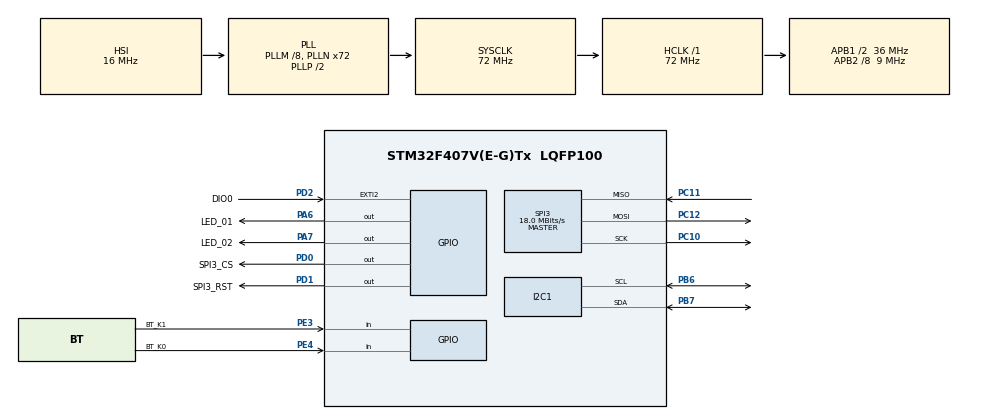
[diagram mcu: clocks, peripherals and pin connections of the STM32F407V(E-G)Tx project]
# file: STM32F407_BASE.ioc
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Mcu.Family=STM32F4
Mcu.Name=STM32F407V(E-G)Tx
Mcu.Package=LQFP100
NVIC.PriorityGroup=NVIC_PRIORITYGROUP_4
NVIC.RCC_IRQn=true\:0\:0\:false\:false\:true\:true\:false\:true
NVIC.TIM1_UP_TIM10_IRQn=true\:0\:0\:false\:false\:true\:true\:true\:true
PA13.Mode=Serial_Wire
PA13.Signal=SYS_JTMS-SWDIO
PA14.Mode=Serial_Wire
PA14.Signal=SYS_JTCK-SWCLK
PA6.GPIO_Label=LED_01
PA6.GPIO_PuPd=GPIO_PULLUP
PA6.Signal=GPIO_Output
PA7.GPIO_Label=LED_02
PA7.GPIO_PuPd=GPIO_PULLUP
PA7.Signal=GPIO_Output
PB6.Mode=I2C
PB6.Signal=I2C1_SCL
PB7.Mode=I2C
PB7.Signal=I2C1_SDA
PC10.Mode=Full_Duplex_Master
PC10.Signal=SPI3_SCK
PC11.Mode=Full_Duplex_Master
PC11.Signal=SPI3_MISO
PC12.Mode=Full_Duplex_Master
PC12.Signal=SPI3_MOSI
PD0.GPIO_Label=SPI3_CS
PD0.PinState=GPIO_PIN_SET
PD0.Signal=GPIO_Output
PD1.GPIO_Label=SPI3_RST
PD1.PinState=GPIO_PIN_SET
PD1.Signal=GPIO_Output
PD2.GPIO_Label=DIO0
PD2.Signal=GPXTI2
PE3.GPIO_Label=BT_K1
PE3.GPIO_PuPd=GPIO_PULLUP
PE3.Signal=GPIO_Input
PE4.GPIO_Label=BT_K0
PE4.GPIO_PuPd=GPIO_PULLUP
PE4.Signal=GPIO_Input
PH0-OSC_IN.Mode=HSE-External-Oscillator
PH0-OSC_IN.Signal=RCC_OSC_IN
PH1-OSC_OUT.Mode=HSE-External-Oscillator
PH1-OSC_OUT.Signal=RCC_OSC_OUT
ProjectManager.HeapSize=0x200
ProjectManager.StackSize=0x400
ProjectManager.TargetToolchain=STM32CubeIDE
RCC.48MHZClocksFreq_Value=36000000
RCC.AHBFreq_Value=72000000
RCC.APB1CLKDivider=RCC_HCLK_DIV2
RCC.APB1Freq_Value=36000000
RCC.APB1TimFreq_Value=72000000
RCC.APB2CLKDivider=RCC_HCLK_DIV8
RCC.APB2Freq_Value=9000000
RCC.APB2TimFreq_Value=18000000
RCC.CortexFreq_Value=72000000
RCC.HCLKFreq_Value=72000000
RCC.HSE_VALUE=25000000
RCC.HSI_VALUE=16000000
RCC.LSE_VALUE=32768
RCC.PLLM=8
RCC.PLLN=72
RCC.SYSCLKFreq_VALUE=72000000
RCC.SYSCLKSource=RCC_SYSCLKSOURCE_PLLCLK
RCC.VCOOutputFreq_Value=144000000
SPI3.BaudRatePrescaler=SPI_BAUDRATEPRESCALER_2
SPI3.CalculateBaudRate=18.0 MBits/s
SPI3.Direction=SPI_DIRECTION_2LINES
SPI3.Mode=SPI_MODE_MASTER
SPI3.VirtualType=VM_MASTER
TIM1.Period=99
TIM1.Prescaler=9000
VP_TIM1_VS_ClockSourceINT.Mode=Internal
board=custom

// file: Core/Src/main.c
/* USER CODE BEGIN Header */
/**
  ******************************************************************************
  * @file           : main.c
  * @brief          : Main program body
  ******************************************************************************
  */
/* USER CODE END Header */
#include "main.h"
#include "i2c-lcd.h"
#include "LoRa_Frame.h"

I2C_HandleTypeDef hi2c1;

SPI_HandleTypeDef hspi3;

TIM_HandleTypeDef htim1;

/* USER CODE BEGIN PV */

uint32_t last_send_tick = 0;
uint32_t send_count = 0;
/* USER CODE END PV */

void SystemClock_Config(void);
static void MX_GPIO_Init(void);
static void MX_SPI3_Init(void);
static void MX_TIM1_Init(void);
static void MX_I2C1_Init(void);

int main(void)
{

  /* MCU Configuration--------------------------------------------------------*/

  /* Reset of all peripherals, Initializes the Flash interface and the Systick. */
  HAL_Init();

  /* Configure the system clock */
  SystemClock_Config();

  /* Initialize all configured peripherals */
  MX_GPIO_Init();
  MX_SPI3_Init();
  MX_TIM1_Init();
  MX_I2C1_Init();

  lcd_init();

  /* USER CODE BEGIN 2 */
  lcd_goto_XY(1, 0);
  lcd_send_string("=== TX_LORA ===");

  while (!Lora_Init(&hspi3,
		  SPI3_CS_GPIO_Port, SPI3_CS_Pin,
		  SPI3_RST_GPIO_Port, SPI3_RST_Pin,
          DIO0_GPIO_Port, DIO0_Pin))
  {
	 lcd_goto_XY(2, 0);
     lcd_send_string("[LORA]: INIT_FAIL");
  }

  lcd_goto_XY(2, 0);
  lcd_send_string("[LORA]: INIT_OK");

  HAL_Delay(1000);

  /* USER CODE END 2 */

  /* Infinite loop */
  while (1)
  {
	  if (HAL_GetTick() - last_send_tick >= 1000)
	  {
		  last_send_tick = HAL_GetTick();
		  send_count++;

		  Lora_Test_Frame(&send_count);

		  if (LoRa_Send_Frame(&lora, TYPE_DEFAULT) == 1)
		  {
		        HAL_GPIO_TogglePin(LED_01_GPIO_Port, LED_01_Pin);
		  }
	  }
  }
}

void SystemClock_Config(void)
{
  RCC_OscInitTypeDef RCC_OscInitStruct = {0};
  RCC_ClkInitTypeDef RCC_ClkInitStruct = {0};

  /** Configure the main internal regulator output voltage
  */
  __HAL_RCC_PWR_CLK_ENABLE();
  __HAL_PWR_VOLTAGESCALING_CONFIG(PWR_REGULATOR_VOLTAGE_SCALE1);

  /** Initializes the RCC Oscillators according to the specified parameters
  * in the RCC_OscInitTypeDef structure.
  */
  RCC_OscInitStruct.OscillatorType = RCC_OSCILLATORTYPE_HSI;
  RCC_OscInitStruct.HSIState = RCC_HSI_ON;
  RCC_OscInitStruct.HSICalibrationValue = RCC_HSICALIBRATION_DEFAULT;
  RCC_OscInitStruct.PLL.PLLState = RCC_PLL_ON;
  RCC_OscInitStruct.PLL.PLLSource = RCC_PLLSOURCE_HSI;
  RCC_OscInitStruct.PLL.PLLM = 8;
  RCC_OscInitStruct.PLL.PLLN = 72;
  RCC_OscInitStruct.PLL.PLLP = RCC_PLLP_DIV2;
  RCC_OscInitStruct.PLL.PLLQ = 4;
  if (HAL_RCC_OscConfig(&RCC_OscInitStruct) != HAL_OK)
  {
    Error_Handler();
  }

  /** Initializes the CPU, AHB and APB buses clocks
  */
  RCC_ClkInitStruct.ClockType = RCC_CLOCKTYPE_HCLK|RCC_CLOCKTYPE_SYSCLK
                              |RCC_CLOCKTYPE_PCLK1|RCC_CLOCKTYPE_PCLK2;
  RCC_ClkInitStruct.SYSCLKSource = RCC_SYSCLKSOURCE_PLLCLK;
  RCC_ClkInitStruct.AHBCLKDivider = RCC_SYSCLK_DIV1;
  RCC_ClkInitStruct.APB1CLKDivider = RCC_HCLK_DIV2;
  RCC_ClkInitStruct.APB2CLKDivider = RCC_HCLK_DIV8;

  if (HAL_RCC_ClockConfig(&RCC_ClkInitStruct, FLASH_LATENCY_2) != HAL_OK)
  {
    Error_Handler();
  }
}

static void MX_I2C1_Init(void)
{

  hi2c1.Instance = I2C1;
  hi2c1.Init.ClockSpeed = 100000;
  hi2c1.Init.DutyCycle = I2C_DUTYCYCLE_2;
  hi2c1.Init.OwnAddress1 = 0;
  hi2c1.Init.AddressingMode = I2C_ADDRESSINGMODE_7BIT;
  hi2c1.Init.DualAddressMode = I2C_DUALADDRESS_DISABLE;
  hi2c1.Init.OwnAddress2 = 0;
  hi2c1.Init.GeneralCallMode = I2C_GENERALCALL_DISABLE;
  hi2c1.Init.NoStretchMode = I2C_NOSTRETCH_DISABLE;
  if (HAL_I2C_Init(&hi2c1) != HAL_OK)
  {
    Error_Handler();
  }

}

static void MX_SPI3_Init(void)
{

  /* SPI3 parameter configuration*/
  hspi3.Instance = SPI3;
  hspi3.Init.Mode = SPI_MODE_MASTER;
  hspi3.Init.Direction = SPI_DIRECTION_2LINES;
  hspi3.Init.DataSize = SPI_DATASIZE_8BIT;
  hspi3.Init.CLKPolarity = SPI_POLARITY_LOW;
  hspi3.Init.CLKPhase = SPI_PHASE_1EDGE;
  hspi3.Init.NSS = SPI_NSS_SOFT;
  hspi3.Init.BaudRatePrescaler = SPI_BAUDRATEPRESCALER_2;
  hspi3.Init.FirstBit = SPI_FIRSTBIT_MSB;
  hspi3.Init.TIMode = SPI_TIMODE_DISABLE;
  hspi3.Init.CRCCalculation = SPI_CRCCALCULATION_DISABLE;
  hspi3.Init.CRCPolynomial = 10;
  if (HAL_SPI_Init(&hspi3) != HAL_OK)
  {
    Error_Handler();
  }

}

static void MX_TIM1_Init(void)
{

  TIM_ClockConfigTypeDef sClockSourceConfig = {0};
  TIM_MasterConfigTypeDef sMasterConfig = {0};

  htim1.Instance = TIM1;
  htim1.Init.Prescaler = 9000;
  htim1.Init.CounterMode = TIM_COUNTERMODE_UP;
  htim1.Init.Period = 99;
  htim1.Init.ClockDivision = TIM_CLOCKDIVISION_DIV1;
  htim1.Init.RepetitionCounter = 0;
  htim1.Init.AutoReloadPreload = TIM_AUTORELOAD_PRELOAD_DISABLE;
  if (HAL_TIM_Base_Init(&htim1) != HAL_OK)
  {
    Error_Handler();
  }
  sClockSourceConfig.ClockSource = TIM_CLOCKSOURCE_INTERNAL;
  if (HAL_TIM_ConfigClockSource(&htim1, &sClockSourceConfig) != HAL_OK)
  {
    Error_Handler();
  }
  sMasterConfig.MasterOutputTrigger = TIM_TRGO_RESET;
  sMasterConfig.MasterSlaveMode = TIM_MASTERSLAVEMODE_DISABLE;
  if (HAL_TIMEx_MasterConfigSynchronization(&htim1, &sMasterConfig) != HAL_OK)
  {
    Error_Handler();
  }

}

static void MX_GPIO_Init(void)
{
  GPIO_InitTypeDef GPIO_InitStruct = {0};

  /* GPIO Ports Clock Enable */
  __HAL_RCC_GPIOE_CLK_ENABLE();
  __HAL_RCC_GPIOH_CLK_ENABLE();
  __HAL_RCC_GPIOA_CLK_ENABLE();
  __HAL_RCC_GPIOC_CLK_ENABLE();
  __HAL_RCC_GPIOD_CLK_ENABLE();
  __HAL_RCC_GPIOB_CLK_ENABLE();

  /*Configure GPIO pin Output Level */
  HAL_GPIO_WritePin(GPIOA, LED_01_Pin|LED_02_Pin, GPIO_PIN_RESET);

  /*Configure GPIO pin Output Level */
  HAL_GPIO_WritePin(GPIOD, SPI3_CS_Pin|SPI3_RST_Pin, GPIO_PIN_SET);

  /*Configure GPIO pins : BT_K1_Pin BT_K0_Pin */
  GPIO_InitStruct.Pin = BT_K1_Pin|BT_K0_Pin;
  GPIO_InitStruct.Mode = GPIO_MODE_INPUT;
  GPIO_InitStruct.Pull = GPIO_PULLUP;
  HAL_GPIO_Init(GPIOE, &GPIO_InitStruct);

  /*Configure GPIO pins : LED_01_Pin LED_02_Pin */
  GPIO_InitStruct.Pin = LED_01_Pin|LED_02_Pin;
  GPIO_InitStruct.Mode = GPIO_MODE_OUTPUT_PP;
  GPIO_InitStruct.Pull = GPIO_PULLUP;
  GPIO_InitStruct.Speed = GPIO_SPEED_FREQ_LOW;
  HAL_GPIO_Init(GPIOA, &GPIO_InitStruct);

  /*Configure GPIO pins : SPI3_CS_Pin SPI3_RST_Pin */
  GPIO_InitStruct.Pin = SPI3_CS_Pin|SPI3_RST_Pin;
  GPIO_InitStruct.Mode = GPIO_MODE_OUTPUT_PP;
  GPIO_InitStruct.Pull = GPIO_NOPULL;
  GPIO_InitStruct.Speed = GPIO_SPEED_FREQ_LOW;
  HAL_GPIO_Init(GPIOD, &GPIO_InitStruct);

  /*Configure GPIO pin : DIO0_Pin */
  GPIO_InitStruct.Pin = DIO0_Pin;
  GPIO_InitStruct.Mode = GPIO_MODE_IT_RISING;
  GPIO_InitStruct.Pull = GPIO_NOPULL;
  HAL_GPIO_Init(DIO0_GPIO_Port, &GPIO_InitStruct);

}

void Error_Handler(void)
{
  __disable_irq();
  while (1)
  {
  }
}
